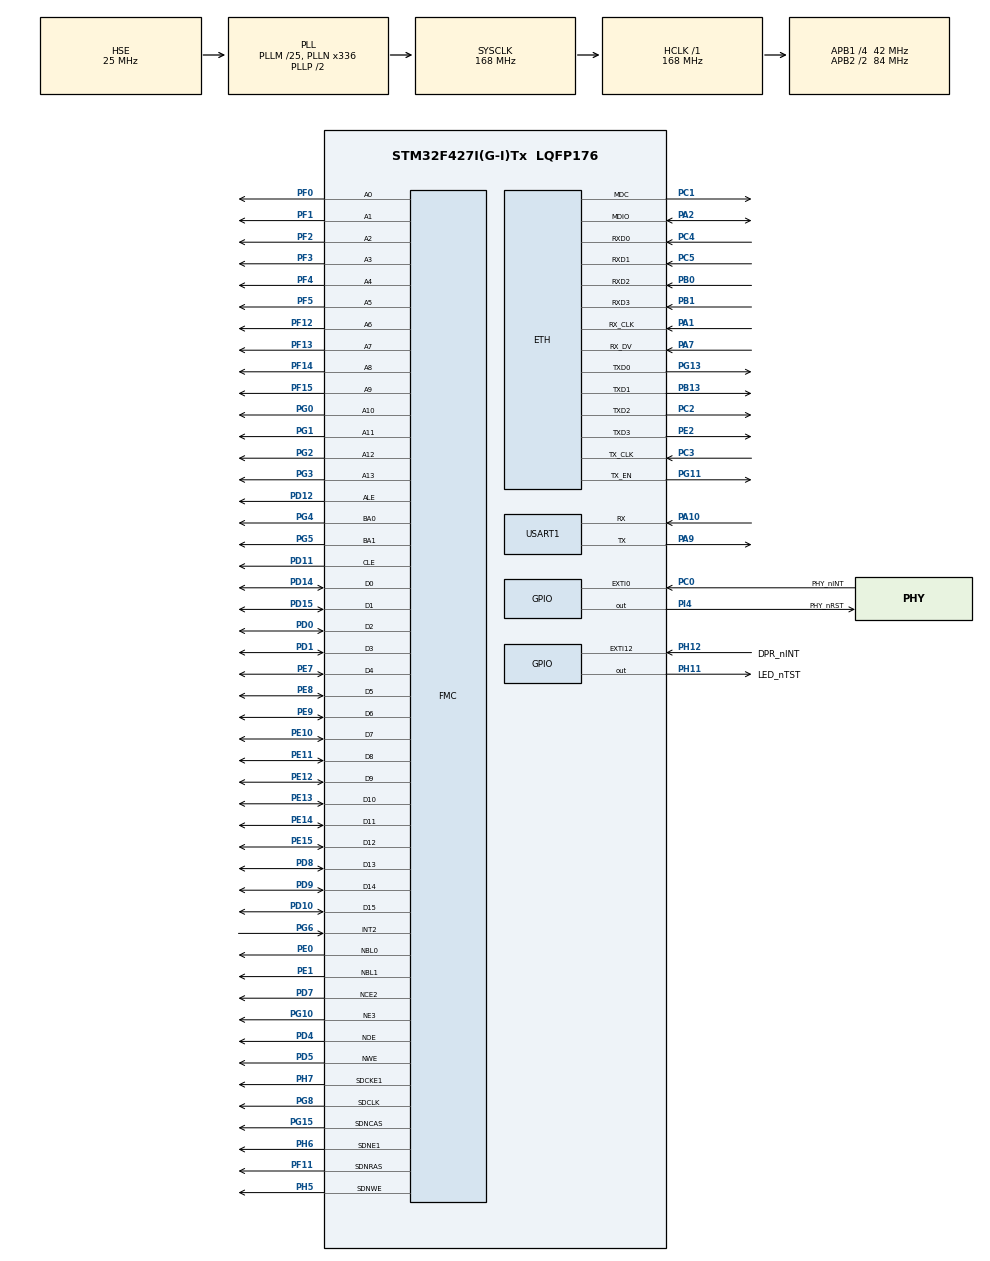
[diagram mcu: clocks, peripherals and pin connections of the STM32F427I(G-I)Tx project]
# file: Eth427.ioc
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ETH.MediaInterface=ETH_MEDIA_INTERFACE_MII
ETH.PHY_Name_MII=userPHY
ETH.PHY_User_Name=KSZ8873
ETH.PhyAddress=1
FMC.AddressSetupTime3=2
FMC.BusTurnAroundDuration3=5
FMC.CASLatency2=FMC_SDRAM_CAS_LATENCY_3
FMC.ColumnBitsNumber2=FMC_SDRAM_COLUMN_BITS_NUM_9
FMC.DataSetupTime3=6
FMC.ExitSelfRefreshDelay2=7
FMC.ExtendedAddressSetupTime3=2
FMC.ExtendedBusTurnAroundDuration3=5
FMC.ExtendedDataSetupTime3=6
FMC.ExtendedMode3=FMC_EXTENDED_MODE_ENABLE
FMC.LoadToActiveDelay2=2
FMC.RCDDelay2=2
FMC.RPDelay2=2
FMC.ReadBurst2=FMC_SDRAM_RBURST_DISABLE
FMC.ReadPipeDelay2=FMC_SDRAM_RPIPE_DELAY_1
FMC.RowCycleDelay2=7
FMC.SDClockPeriod2=FMC_SDRAM_CLOCK_PERIOD_2
FMC.SelfRefreshTime2=4
FMC.WriteOperation3=FMC_WRITE_OPERATION_ENABLE
FMC.WriteRecoveryTime2=3
FREERTOS.Tasks01=defaultTask,0,128,StartDefaultTask,Default,NULL
FREERTOS.configTOTAL_HEAP_SIZE=65536
LWIP.CHECKSUM_BY_HARDWARE=1
LWIP.GATEWAY_ADDRESS=192.168.001.001
LWIP.ICMP_TTL=63
LWIP.IP_ADDRESS=192.168.001.155
LWIP.LWIP_DHCP=0
LWIP.LWIP_NETIF_LINK_CALLBACK=0
LWIP.LWIP_SNTP=1
LWIP.LWIP_STATS=1
LWIP.MEMP_MEM_MALLOC=0
LWIP.MEMP_NUM_NETCONN=8
LWIP.MEMP_NUM_TCP_PCB=8
LWIP.MEMP_NUM_TCP_PCB_LISTEN=3
LWIP.MEMP_NUM_UDP_PCB=4
LWIP.MEM_SIZE=1600
LWIP.NETMASK_ADDRESS=255.255.255.000
LWIP.TCP_TTL=64
LWIP.Version=v2.0.3_Cube
Mcu.Family=STM32F4
Mcu.Name=STM32F427I(G-I)Tx
Mcu.Package=LQFP176
NVIC.ETH_IRQn=true\:5\:0\:false\:false\:true\:true\:true
NVIC.PriorityGroup=NVIC_PRIORITYGROUP_4
NVIC.TIM8_UP_TIM13_IRQn=true\:0\:0\:false\:false\:true\:false\:false
NVIC.TimeBase=TIM8_UP_TIM13_IRQn
NVIC.TimeBaseIP=TIM13
PA1.Mode=MII Full Duplex Only
PA1.Signal=ETH_RX_CLK
PA10.Mode=Asynchronous
PA10.Signal=USART1_RX
PA13.Mode=JTAG_5_pins
PA13.Signal=SYS_JTMS-SWDIO
PA14.Mode=JTAG_5_pins
PA14.Signal=SYS_JTCK-SWCLK
PA15.Mode=JTAG_5_pins
PA15.Signal=SYS_JTDI
PA2.Mode=MII Full Duplex Only
PA2.Signal=ETH_MDIO
PA3.Signal=ETH_COL
PA7.Mode=MII Full Duplex Only
PA7.Signal=ETH_RX_DV
PA9.Mode=Asynchronous
PA9.Signal=USART1_TX
PB0.Mode=MII Full Duplex Only
PB0.Signal=ETH_RXD2
PB1.Mode=MII Full Duplex Only
PB1.Signal=ETH_RXD3
PB13.Mode=MII Full Duplex Only
PB13.Signal=ETH_TXD1
PB3.Mode=JTAG_5_pins
PB3.Signal=SYS_JTDO-SWO
PB4.Mode=JTAG_5_pins
PB4.Signal=SYS_JTRST
PC0.GPIO_Label=PHY_nINT
PC0.GPIO_ModeDefaultEXTI=GPIO_MODE_IT_FALLING
PC0.GPIO_PuPd=GPIO_PULLUP
PC0.Signal=GPXTI0
PC1.Mode=MII Full Duplex Only
PC1.Signal=ETH_MDC
PC14/OSC32_IN.Mode=LSE-External-Oscillator
PC14/OSC32_IN.Signal=RCC_OSC32_IN
PC15/OSC32_OUT.Mode=LSE-External-Oscillator
PC15/OSC32_OUT.Signal=RCC_OSC32_OUT
PC2.Mode=MII Full Duplex Only
PC2.Signal=ETH_TXD2
PC3.Mode=MII Full Duplex Only
PC3.Signal=ETH_TX_CLK
PC4.Mode=MII Full Duplex Only
PC4.Signal=ETH_RXD0
PC5.Mode=MII Full Duplex Only
PC5.Signal=ETH_RXD1
PD0.Signal=FMC_D2_DA2
PD1.Signal=FMC_D3_DA3
PD10.Signal=FMC_D15_DA15
PD11.Signal=FMC_A16_CLE
PD12.Signal=FMC_A17_ALE
PD14.Signal=FMC_D0_DA0
PD15.Signal=FMC_D1_DA1
PD4.Signal=FMC_NOE
PD5.Signal=FMC_NWE
PD7.Mode=NandChipSelect2_1
PD7.Signal=FMC_NCE2
PD8.Signal=FMC_D13_DA13
PD9.Signal=FMC_D14_DA14
PE0.Signal=FMC_NBL0
PE1.Signal=FMC_NBL1
PE10.Signal=FMC_D7_DA7
PE11.Signal=FMC_D8_DA8
PE12.Signal=FMC_D9_DA9
PE13.Signal=FMC_D10_DA10
PE14.Signal=FMC_D11_DA11
PE15.Signal=FMC_D12_DA12
PE2.Mode=MII Full Duplex Only
PE2.Signal=ETH_TXD3
PE7.Signal=FMC_D4_DA4
PE8.Signal=FMC_D5_DA5
PE9.Signal=FMC_D6_DA6
PF0.Signal=FMC_A0
PF1.Signal=FMC_A1
PF11.Signal=FMC_SDNRAS
PF12.Signal=FMC_A6
PF13.Signal=FMC_A7
PF14.Signal=FMC_A8
PF15.Signal=FMC_A9
PF2.Signal=FMC_A2
PF3.Signal=FMC_A3
PF4.Signal=FMC_A4
PF5.Signal=FMC_A5
PG0.Signal=FMC_A10
PG1.Signal=FMC_A11
PG10.Mode=NorPsramChipSelect3_3
PG10.Signal=FMC_NE3
PG11.Mode=MII Full Duplex Only
PG11.Signal=ETH_TX_EN
PG13.Mode=MII Full Duplex Only
PG13.Signal=ETH_TXD0
PG15.Signal=FMC_SDNCAS
PG2.Signal=FMC_A12
PG3.Signal=FMC_A13
PG4.Signal=FMC_A14_BA0
PG5.Signal=FMC_A15_BA1
PG6.Signal=FMC_INT2
PG8.Signal=FMC_SDCLK
PH0/OSC_IN.Mode=HSE-External-Oscillator
PH0/OSC_IN.Signal=RCC_OSC_IN
PH1/OSC_OUT.Mode=HSE-External-Oscillator
PH1/OSC_OUT.Signal=RCC_OSC_OUT
PH11.GPIO_Label=LED_nTST
PH11.Signal=GPIO_Output
PH12.GPIO_Label=DPR_nINT
PH12.Signal=GPXTI12
PH5.Signal=FMC_SDNWE
PH6.Mode=SdramChipSelect2_2
PH6.Signal=FMC_SDNE1
PH7.Mode=SdramChipSelect2_2
PH7.Signal=FMC_SDCKE1
PI4.GPIO_Label=PHY_nRST
PI4.Signal=GPIO_Output
ProjectManager.HeapSize=0x10000
ProjectManager.StackSize=0x2000
ProjectManager.TargetToolchain=EWARM V7
RCC.48MHZClocksFreq_Value=84000000
RCC.AHBFreq_Value=168000000
RCC.APB1CLKDivider=RCC_HCLK_DIV4
RCC.APB1Freq_Value=42000000
RCC.APB1TimFreq_Value=84000000
RCC.APB2CLKDivider=RCC_HCLK_DIV2
RCC.APB2Freq_Value=84000000
RCC.APB2TimFreq_Value=168000000
RCC.CortexFreq_Value=168000000
RCC.HCLKFreq_Value=168000000
RCC.HSE_VALUE=25000000
RCC.HSI_VALUE=16000000
RCC.PLLM=25
RCC.PLLN=336
RCC.PLLSourceVirtual=RCC_PLLSOURCE_HSE
RCC.SYSCLKFreq_VALUE=168000000
RCC.SYSCLKSource=RCC_SYSCLKSOURCE_PLLCLK
RCC.VCOOutputFreq_Value=336000000
SH.FMC_A0.0=FMC_A0,14b-a3
SH.FMC_A0.1=FMC_A0,13b-sda2
SH.FMC_A1.0=FMC_A1,14b-a3
SH.FMC_A1.1=FMC_A1,13b-sda2
SH.FMC_A10.0=FMC_A10,14b-a3
SH.FMC_A10.1=FMC_A10,13b-sda2
SH.FMC_A11.0=FMC_A11,14b-a3
SH.FMC_A11.1=FMC_A11,13b-sda2
SH.FMC_A12.0=FMC_A12,14b-a3
SH.FMC_A12.1=FMC_A12,13b-sda2
SH.FMC_A13.0=FMC_A13,14b-a3
SH.FMC_A14_BA0.0=FMC_BA0,FourSdramBanks2
SH.FMC_A15_BA1.0=FMC_BA1,FourSdramBanks2
SH.FMC_A16_CLE.0=FMC_CLE,8b-dmux1
SH.FMC_A17_ALE.0=FMC_ALE,8b-dmux1
SH.FMC_A2.0=FMC_A2,14b-a3
SH.FMC_A2.1=FMC_A2,13b-sda2
SH.FMC_A3.0=FMC_A3,14b-a3
SH.FMC_A3.1=FMC_A3,13b-sda2
SH.FMC_A4.0=FMC_A4,14b-a3
SH.FMC_A4.1=FMC_A4,13b-sda2
SH.FMC_A5.0=FMC_A5,14b-a3
SH.FMC_A5.1=FMC_A5,13b-sda2
SH.FMC_A6.0=FMC_A6,14b-a3
SH.FMC_A6.1=FMC_A6,13b-sda2
SH.FMC_A7.0=FMC_A7,14b-a3
SH.FMC_A7.1=FMC_A7,13b-sda2
SH.FMC_A8.0=FMC_A8,14b-a3
SH.FMC_A8.1=FMC_A8,13b-sda2
SH.FMC_A9.0=FMC_A9,14b-a3
SH.FMC_A9.1=FMC_A9,13b-sda2
SH.FMC_D0_DA0.0=FMC_D0,16b-d3
SH.FMC_D0_DA0.1=FMC_D0,8b-dmux1
SH.FMC_D0_DA0.2=FMC_D0,sd-16b-d2
SH.FMC_D10_DA10.0=FMC_D10,16b-d3
SH.FMC_D10_DA10.1=FMC_D10,sd-16b-d2
SH.FMC_D11_DA11.0=FMC_D11,16b-d3
SH.FMC_D11_DA11.1=FMC_D11,sd-16b-d2
SH.FMC_D12_DA12.0=FMC_D12,16b-d3
SH.FMC_D12_DA12.1=FMC_D12,sd-16b-d2
SH.FMC_D13_DA13.0=FMC_D13,16b-d3
SH.FMC_D13_DA13.1=FMC_D13,sd-16b-d2
SH.FMC_D14_DA14.0=FMC_D14,16b-d3
SH.FMC_D14_DA14.1=FMC_D14,sd-16b-d2
SH.FMC_D15_DA15.0=FMC_D15,16b-d3
SH.FMC_D15_DA15.1=FMC_D15,sd-16b-d2
SH.FMC_D1_DA1.0=FMC_D1,16b-d3
SH.FMC_D1_DA1.1=FMC_D1,8b-dmux1
SH.FMC_D1_DA1.2=FMC_D1,sd-16b-d2
SH.FMC_D2_DA2.0=FMC_D2,16b-d3
SH.FMC_D2_DA2.1=FMC_D2,8b-dmux1
SH.FMC_D2_DA2.2=FMC_D2,sd-16b-d2
SH.FMC_D3_DA3.0=FMC_D3,16b-d3
SH.FMC_D3_DA3.1=FMC_D3,8b-dmux1
SH.FMC_D3_DA3.2=FMC_D3,sd-16b-d2
SH.FMC_D4_DA4.0=FMC_D4,16b-d3
SH.FMC_D4_DA4.1=FMC_D4,8b-dmux1
SH.FMC_D4_DA4.2=FMC_D4,sd-16b-d2
SH.FMC_D5_DA5.0=FMC_D5,16b-d3
SH.FMC_D5_DA5.1=FMC_D5,8b-dmux1
SH.FMC_D5_DA5.2=FMC_D5,sd-16b-d2
SH.FMC_D6_DA6.0=FMC_D6,16b-d3
SH.FMC_D6_DA6.1=FMC_D6,8b-dmux1
SH.FMC_D6_DA6.2=FMC_D6,sd-16b-d2
SH.FMC_D7_DA7.0=FMC_D7,16b-d3
SH.FMC_D7_DA7.1=FMC_D7,8b-dmux1
SH.FMC_D7_DA7.2=FMC_D7,sd-16b-d2
SH.FMC_D8_DA8.0=FMC_D8,16b-d3
SH.FMC_D8_DA8.1=FMC_D8,sd-16b-d2
SH.FMC_D9_DA9.0=FMC_D9,16b-d3
SH.FMC_D9_DA9.1=FMC_D9,sd-16b-d2
SH.FMC_INT2.0=FMC_INT2,Interrupt21
SH.FMC_NBL0.0=FMC_NBL0,2ByteEnable3
SH.FMC_NBL0.1=FMC_NBL0,Sd2ByteEnable2
SH.FMC_NBL1.0=FMC_NBL1,2ByteEnable3
SH.FMC_NBL1.1=FMC_NBL1,Sd2ByteEnable2
SH.FMC_NOE.0=FMC_NOE,Sram3
SH.FMC_NOE.1=FMC_NOE,8b-dmux1
SH.FMC_NWE.0=FMC_NWE,Sram3
SH.FMC_NWE.1=FMC_NWE,8b-dmux1
SH.FMC_SDCLK.0=FMC_SDCLK,13b-sda2
SH.FMC_SDNCAS.0=FMC_SDNCAS,13b-sda2
SH.FMC_SDNRAS.0=FMC_SDNRAS,13b-sda2
SH.FMC_SDNWE.0=FMC_SDNWE,13b-sda2
USART1.VirtualMode=VM_ASYNC
VP_FREERTOS_VS_ENABLE.Mode=Enabled
VP_LWIP_VS_Enabled.Mode=Enabled
VP_SYS_VS_tim13.Mode=TIM13
board=custom

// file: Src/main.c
/* USER CODE BEGIN Header */
/**
  ******************************************************************************
  * @file           : main.c
  * @brief          : Main program body
  ******************************************************************************
  ** This notice applies to any and all portions of this file
  * that are not between comment pairs USER CODE BEGIN and
  * USER CODE END. Other portions of this file, whether
  * inserted by the user or by software development tools
  * are owned by their respective copyright owners.
  *
  * COPYRIGHT(c) 2019 STMicroelectronics
  *
  * Redistribution and use in source and binary forms, with or without modification,
  * are permitted provided that the following conditions are met:
  *   1. Redistributions of source code must retain the above copyright notice,
  *      this list of conditions and the following disclaimer.
  *   2. Redistributions in binary form must reproduce the above copyright notice,
  *      this list of conditions and the following disclaimer in the documentation
  *      and/or other materials provided with the distribution.
  *   3. Neither the name of STMicroelectronics nor the names of its contributors
  *      may be used to endorse or promote products derived from this software
  *      without specific prior written permission.
  *
  * THIS SOFTWARE IS PROVIDED BY THE COPYRIGHT HOLDERS AND CONTRIBUTORS "AS IS"
  * AND ANY EXPRESS OR IMPLIED WARRANTIES, INCLUDING, BUT NOT LIMITED TO, THE
  * IMPLIED WARRANTIES OF MERCHANTABILITY AND FITNESS FOR A PARTICULAR PURPOSE ARE
  * DISCLAIMED. IN NO EVENT SHALL THE COPYRIGHT HOLDER OR CONTRIBUTORS BE LIABLE
  * FOR ANY DIRECT, INDIRECT, INCIDENTAL, SPECIAL, EXEMPLARY, OR CONSEQUENTIAL
  * DAMAGES (INCLUDING, BUT NOT LIMITED TO, PROCUREMENT OF SUBSTITUTE GOODS OR
  * SERVICES; LOSS OF USE, DATA, OR PROFITS; OR BUSINESS INTERRUPTION) HOWEVER
  * CAUSED AND ON ANY THEORY OF LIABILITY, WHETHER IN CONTRACT, STRICT LIABILITY,
  * OR TORT (INCLUDING NEGLIGENCE OR OTHERWISE) ARISING IN ANY WAY OUT OF THE USE
  * OF THIS SOFTWARE, EVEN IF ADVISED OF THE POSSIBILITY OF SUCH DAMAGE.
  *
  ******************************************************************************
  */
/* USER CODE END Header */

#include "main.h"
#include "cmsis_os.h"
#include "lwip.h"

/* USER CODE BEGIN Includes */
// by Sooan Choi
#include "MdTcpSrv.h"		// Modbus Tcp
#include "dpram.h"

/* USER CODE END Includes */

UART_HandleTypeDef huart1;

SRAM_HandleTypeDef hsram3;
NAND_HandleTypeDef hnand1;
SDRAM_HandleTypeDef hsdram2;

osThreadId defaultTaskHandle;

void SystemClock_Config(void);
static void MX_GPIO_Init(void);
static void MX_USART1_UART_Init(void);
static void MX_FMC_Init(void);
void StartDefaultTask(void const * argument);

/* USER CODE BEGIN PFP */
static void BSP_SDRAM_Initialization_Sequence(SDRAM_HandleTypeDef *hsdram, FMC_SDRAM_CommandTypeDef *Command);
/* USER CODE END PFP */

/* USER CODE BEGIN 0 */
#ifdef __GNUC__
int  _write(int file, char *ptr, int len)
{
	HAL_UART_Transmit(&huart1, (uint8_t*)ptr, len, 10 );

	return len;
}
#else
int fputc(int ch, FILE *f)
{
  HAL_UART_Transmit(&huart1, (uint8_t *)&ch, 1, 0xFFFF);

  return ch;
}
#endif /* __GNUC__ */
/* USER CODE END 0 */

int main(void)
{

  /* MCU Configuration--------------------------------------------------------*/

  /* Reset of all peripherals, Initializes the Flash interface and the Systick. */
  HAL_Init();

  /* Configure the system clock */
  SystemClock_Config();

  /* Initialize all configured peripherals */
  MX_GPIO_Init();
  MX_USART1_UART_Init();
  MX_FMC_Init();
  /* USER CODE BEGIN 2 */

	FMC_SDRAM_CommandTypeDef Command;
	BSP_SDRAM_Initialization_Sequence(&hsdram2, &Command);

	printf("Promet-S Ethernet for STM32F4xx. Ver 1.0b0\r\n");
	printf("Compiled on %s, %s\r\n", __TIME__, __DATE__);
	printf("Copywrite by Sooan. Neopis Co., Ltd. South Korea\r\n\n");

	printf("Running on System Clock Speed %3uMHz\r\n", (unsigned)HAL_RCC_GetSysClockFreq()/1000000);
	printf("HCLK   = %3uMHz\r\n", (unsigned)HAL_RCC_GetHCLKFreq()/1000000);
	printf("PCLK1  = %3uMHz\r\n", (unsigned)HAL_RCC_GetPCLK1Freq()/1000000);
	printf("PCLK2  = %3uMHz\r\n", (unsigned)HAL_RCC_GetPCLK2Freq()/1000000);
	printf("\n");

	dpram_init();

  /* USER CODE END 2 */

  /* Create the thread(s) */
  /* definition and creation of defaultTask */
  osThreadDef(defaultTask, StartDefaultTask, osPriorityNormal, 0, 128);
  defaultTaskHandle = osThreadCreate(osThread(defaultTask), NULL);

  /* Start scheduler */
  osKernelStart();

  /* We should never get here as control is now taken by the scheduler */

  /* Infinite loop */
  while (1)
  {

  }
}

void SystemClock_Config(void)
{
  RCC_OscInitTypeDef RCC_OscInitStruct = {0};
  RCC_ClkInitTypeDef RCC_ClkInitStruct = {0};

  /**Configure the main internal regulator output voltage
  */
  __HAL_RCC_PWR_CLK_ENABLE();
  __HAL_PWR_VOLTAGESCALING_CONFIG(PWR_REGULATOR_VOLTAGE_SCALE1);
  /**Initializes the CPU, AHB and APB busses clocks
  */
  RCC_OscInitStruct.OscillatorType = RCC_OSCILLATORTYPE_HSE;
  RCC_OscInitStruct.HSEState = RCC_HSE_ON;
  RCC_OscInitStruct.PLL.PLLState = RCC_PLL_ON;
  RCC_OscInitStruct.PLL.PLLSource = RCC_PLLSOURCE_HSE;
  RCC_OscInitStruct.PLL.PLLM = 25;
  RCC_OscInitStruct.PLL.PLLN = 336;
  RCC_OscInitStruct.PLL.PLLP = RCC_PLLP_DIV2;
  RCC_OscInitStruct.PLL.PLLQ = 4;
  if (HAL_RCC_OscConfig(&RCC_OscInitStruct) != HAL_OK)
  {
    Error_Handler();
  }
  /**Initializes the CPU, AHB and APB busses clocks
  */
  RCC_ClkInitStruct.ClockType = RCC_CLOCKTYPE_HCLK|RCC_CLOCKTYPE_SYSCLK
                              |RCC_CLOCKTYPE_PCLK1|RCC_CLOCKTYPE_PCLK2;
  RCC_ClkInitStruct.SYSCLKSource = RCC_SYSCLKSOURCE_PLLCLK;
  RCC_ClkInitStruct.AHBCLKDivider = RCC_SYSCLK_DIV1;
  RCC_ClkInitStruct.APB1CLKDivider = RCC_HCLK_DIV4;
  RCC_ClkInitStruct.APB2CLKDivider = RCC_HCLK_DIV2;

  if (HAL_RCC_ClockConfig(&RCC_ClkInitStruct, FLASH_LATENCY_5) != HAL_OK)
  {
    Error_Handler();
  }
}

static void MX_USART1_UART_Init(void)
{

  huart1.Instance = USART1;
  huart1.Init.BaudRate = 115200;
  huart1.Init.WordLength = UART_WORDLENGTH_8B;
  huart1.Init.StopBits = UART_STOPBITS_1;
  huart1.Init.Parity = UART_PARITY_NONE;
  huart1.Init.Mode = UART_MODE_TX_RX;
  huart1.Init.HwFlowCtl = UART_HWCONTROL_NONE;
  huart1.Init.OverSampling = UART_OVERSAMPLING_16;
  if (HAL_UART_Init(&huart1) != HAL_OK)
  {
    Error_Handler();
  }

}

/* FMC initialization function */
static void MX_FMC_Init(void)
{
  FMC_NORSRAM_TimingTypeDef Timing;
  FMC_NORSRAM_TimingTypeDef ExtTiming;
  FMC_NAND_PCC_TimingTypeDef ComSpaceTiming;
  FMC_NAND_PCC_TimingTypeDef AttSpaceTiming;
  FMC_SDRAM_TimingTypeDef SdramTiming;

  /** Perform the SRAM3 memory initialization sequence
  */
  hsram3.Instance = FMC_NORSRAM_DEVICE;
  hsram3.Extended = FMC_NORSRAM_EXTENDED_DEVICE;
  /* hsram3.Init */
  hsram3.Init.NSBank = FMC_NORSRAM_BANK3;
  hsram3.Init.DataAddressMux = FMC_DATA_ADDRESS_MUX_DISABLE;
  hsram3.Init.MemoryType = FMC_MEMORY_TYPE_SRAM;
  hsram3.Init.MemoryDataWidth = FMC_NORSRAM_MEM_BUS_WIDTH_16;
  hsram3.Init.BurstAccessMode = FMC_BURST_ACCESS_MODE_DISABLE;
  hsram3.Init.WaitSignalPolarity = FMC_WAIT_SIGNAL_POLARITY_LOW;
  hsram3.Init.WrapMode = FMC_WRAP_MODE_DISABLE;
  hsram3.Init.WaitSignalActive = FMC_WAIT_TIMING_BEFORE_WS;
  hsram3.Init.WriteOperation = FMC_WRITE_OPERATION_ENABLE;
  hsram3.Init.WaitSignal = FMC_WAIT_SIGNAL_DISABLE;
  hsram3.Init.ExtendedMode = FMC_EXTENDED_MODE_ENABLE;
  hsram3.Init.AsynchronousWait = FMC_ASYNCHRONOUS_WAIT_DISABLE;
  hsram3.Init.WriteBurst = FMC_WRITE_BURST_DISABLE;
  hsram3.Init.ContinuousClock = FMC_CONTINUOUS_CLOCK_SYNC_ONLY;
  hsram3.Init.PageSize = FMC_PAGE_SIZE_NONE;
  /* Timing */
  Timing.AddressSetupTime = 2;
  Timing.AddressHoldTime = 15;
  Timing.DataSetupTime = 6;
  Timing.BusTurnAroundDuration = 5;
  Timing.CLKDivision = 16;
  Timing.DataLatency = 17;
  Timing.AccessMode = FMC_ACCESS_MODE_A;
  /* ExtTiming */
  ExtTiming.AddressSetupTime = 2;
  ExtTiming.AddressHoldTime = 15;
  ExtTiming.DataSetupTime = 6;
  ExtTiming.BusTurnAroundDuration = 5;
  ExtTiming.CLKDivision = 16;
  ExtTiming.DataLatency = 17;
  ExtTiming.AccessMode = FMC_ACCESS_MODE_A;

  if (HAL_SRAM_Init(&hsram3, &Timing, &ExtTiming) != HAL_OK)
  {
    Error_Handler( );
  }

  /** Perform the NAND1 memory initialization sequence
  */
  hnand1.Instance = FMC_NAND_DEVICE;
  /* hnand1.Init */
  hnand1.Init.NandBank = FMC_NAND_BANK2;
  hnand1.Init.Waitfeature = FMC_NAND_PCC_WAIT_FEATURE_ENABLE;
  hnand1.Init.MemoryDataWidth = FMC_NAND_PCC_MEM_BUS_WIDTH_8;
  hnand1.Init.EccComputation = FMC_NAND_ECC_DISABLE;
  hnand1.Init.ECCPageSize = FMC_NAND_ECC_PAGE_SIZE_256BYTE;
  hnand1.Init.TCLRSetupTime = 0;
  hnand1.Init.TARSetupTime = 0;
  /* hnand1.Config */
  hnand1.Config.PageSize = 0;
  hnand1.Config.SpareAreaSize = 0;
  hnand1.Config.BlockSize = 0;
  hnand1.Config.BlockNbr = 0;
  hnand1.Config.PlaneNbr = 0;
  hnand1.Config.PlaneSize = 0;
  hnand1.Config.ExtraCommandEnable = DISABLE;
  /* ComSpaceTiming */
  ComSpaceTiming.SetupTime = 252;
  ComSpaceTiming.WaitSetupTime = 252;
  ComSpaceTiming.HoldSetupTime = 252;
  ComSpaceTiming.HiZSetupTime = 252;
  /* AttSpaceTiming */
  AttSpaceTiming.SetupTime = 252;
  AttSpaceTiming.WaitSetupTime = 252;
  AttSpaceTiming.HoldSetupTime = 252;
  AttSpaceTiming.HiZSetupTime = 252;

  if (HAL_NAND_Init(&hnand1, &ComSpaceTiming, &AttSpaceTiming) != HAL_OK)
  {
    Error_Handler( );
  }

  /** Perform the SDRAM2 memory initialization sequence
  */
  hsdram2.Instance = FMC_SDRAM_DEVICE;
  /* hsdram2.Init */
  hsdram2.Init.SDBank = FMC_SDRAM_BANK2;
  hsdram2.Init.ColumnBitsNumber = FMC_SDRAM_COLUMN_BITS_NUM_9;
  hsdram2.Init.RowBitsNumber = FMC_SDRAM_ROW_BITS_NUM_13;
  hsdram2.Init.MemoryDataWidth = FMC_SDRAM_MEM_BUS_WIDTH_16;
  hsdram2.Init.InternalBankNumber = FMC_SDRAM_INTERN_BANKS_NUM_4;
  hsdram2.Init.CASLatency = FMC_SDRAM_CAS_LATENCY_3;
  hsdram2.Init.WriteProtection = FMC_SDRAM_WRITE_PROTECTION_DISABLE;
  hsdram2.Init.SDClockPeriod = FMC_SDRAM_CLOCK_PERIOD_2;
  hsdram2.Init.ReadBurst = FMC_SDRAM_RBURST_DISABLE;
  hsdram2.Init.ReadPipeDelay = FMC_SDRAM_RPIPE_DELAY_1;
  /* SdramTiming */
  SdramTiming.LoadToActiveDelay = 2;
  SdramTiming.ExitSelfRefreshDelay = 7;
  SdramTiming.SelfRefreshTime = 4;
  SdramTiming.RowCycleDelay = 7;
  SdramTiming.WriteRecoveryTime = 3;
  SdramTiming.RPDelay = 2;
  SdramTiming.RCDDelay = 2;

  if (HAL_SDRAM_Init(&hsdram2, &SdramTiming) != HAL_OK)
  {
    Error_Handler( );
  }

}

static void MX_GPIO_Init(void)
{
  GPIO_InitTypeDef GPIO_InitStruct = {0};

  /* GPIO Ports Clock Enable */
  __HAL_RCC_GPIOE_CLK_ENABLE();
  __HAL_RCC_GPIOC_CLK_ENABLE();
  __HAL_RCC_GPIOF_CLK_ENABLE();
  __HAL_RCC_GPIOH_CLK_ENABLE();
  __HAL_RCC_GPIOA_CLK_ENABLE();
  __HAL_RCC_GPIOB_CLK_ENABLE();
  __HAL_RCC_GPIOG_CLK_ENABLE();
  __HAL_RCC_GPIOD_CLK_ENABLE();
  __HAL_RCC_GPIOI_CLK_ENABLE();

  /*Configure GPIO pin Output Level */
  HAL_GPIO_WritePin(LED_nTST_GPIO_Port, LED_nTST_Pin, GPIO_PIN_RESET);

  /*Configure GPIO pin Output Level */
  HAL_GPIO_WritePin(PHY_nRST_GPIO_Port, PHY_nRST_Pin, GPIO_PIN_RESET);

  /*Configure GPIO pin : PHY_nINT_Pin */
  GPIO_InitStruct.Pin = PHY_nINT_Pin;
  GPIO_InitStruct.Mode = GPIO_MODE_IT_FALLING;
  GPIO_InitStruct.Pull = GPIO_PULLUP;
  HAL_GPIO_Init(PHY_nINT_GPIO_Port, &GPIO_InitStruct);

  /*Configure GPIO pin : LED_nTST_Pin */
  GPIO_InitStruct.Pin = LED_nTST_Pin;
  GPIO_InitStruct.Mode = GPIO_MODE_OUTPUT_PP;
  GPIO_InitStruct.Pull = GPIO_NOPULL;
  GPIO_InitStruct.Speed = GPIO_SPEED_FREQ_LOW;
  HAL_GPIO_Init(LED_nTST_GPIO_Port, &GPIO_InitStruct);

  /*Configure GPIO pin : DPR_nINT_Pin */
  GPIO_InitStruct.Pin = DPR_nINT_Pin;
  GPIO_InitStruct.Mode = GPIO_MODE_IT_RISING;
  GPIO_InitStruct.Pull = GPIO_NOPULL;
  HAL_GPIO_Init(DPR_nINT_GPIO_Port, &GPIO_InitStruct);

  /*Configure GPIO pin : PHY_nRST_Pin */
  GPIO_InitStruct.Pin = PHY_nRST_Pin;
  GPIO_InitStruct.Mode = GPIO_MODE_OUTPUT_PP;
  GPIO_InitStruct.Pull = GPIO_NOPULL;
  GPIO_InitStruct.Speed = GPIO_SPEED_FREQ_LOW;
  HAL_GPIO_Init(PHY_nRST_GPIO_Port, &GPIO_InitStruct);

}

/* USER CODE BEGIN 4 */
#define SDRAM_TIMEOUT							((uint32_t)0x1000)
#define REFRESH_COUNT							((uint32_t)0x1386)
#define SDRAM_MODEREG_BURST_LENGTH_1             ((uint16_t)0x0000)
#define SDRAM_MODEREG_BURST_LENGTH_2             ((uint16_t)0x0001)
#define SDRAM_MODEREG_BURST_LENGTH_4             ((uint16_t)0x0002)
#define SDRAM_MODEREG_BURST_LENGTH_8             ((uint16_t)0x0004)
#define SDRAM_MODEREG_BURST_TYPE_SEQUENTIAL      ((uint16_t)0x0000)
#define SDRAM_MODEREG_BURST_TYPE_INTERLEAVED     ((uint16_t)0x0008)
#define SDRAM_MODEREG_CAS_LATENCY_2              ((uint16_t)0x0020)
#define SDRAM_MODEREG_CAS_LATENCY_3              ((uint16_t)0x0030)
#define SDRAM_MODEREG_OPERATING_MODE_STANDARD    ((uint16_t)0x0000)
#define SDRAM_MODEREG_WRITEBURST_MODE_PROGRAMMED ((uint16_t)0x0000)
#define SDRAM_MODEREG_WRITEBURST_MODE_SINGLE     ((uint16_t)0x0200)

static void BSP_SDRAM_Initialization_Sequence(SDRAM_HandleTypeDef *hsdram, FMC_SDRAM_CommandTypeDef *Command)
{
  __IO uint32_t tmpmrd =0;
  /* Step 3:  Configure a clock configuration enable command */
  Command->CommandMode = FMC_SDRAM_CMD_CLK_ENABLE;
  Command->CommandTarget = FMC_SDRAM_CMD_TARGET_BANK2;
  Command->AutoRefreshNumber = 1;
  Command->ModeRegisterDefinition = 0;

  /* Send the command */
  HAL_SDRAM_SendCommand(hsdram, Command, SDRAM_TIMEOUT);

  /* Step 4: Insert 100 us minimum delay */
  /* Inserted delay is equal to 10 ms due to systick time base unit (ms) */
  HAL_Delay(10);

  /* Step 5: Configure a PALL (precharge all) command */
  Command->CommandMode = FMC_SDRAM_CMD_PALL;
  Command->CommandTarget = FMC_SDRAM_CMD_TARGET_BANK2;
  Command->AutoRefreshNumber = 1;
  Command->ModeRegisterDefinition = 0;

  /* Send the command */
  HAL_SDRAM_SendCommand(hsdram, Command, SDRAM_TIMEOUT);

  /* Step 6 : Configure a Auto-Refresh command */
  Command->CommandMode = FMC_SDRAM_CMD_AUTOREFRESH_MODE;
  Command->CommandTarget = FMC_SDRAM_CMD_TARGET_BANK2;
  Command->AutoRefreshNumber = 4;
  Command->ModeRegisterDefinition = 0;

  /* Send the command */
  HAL_SDRAM_SendCommand(hsdram, Command, SDRAM_TIMEOUT);

  /* Step 7: Program the external memory mode register */
  tmpmrd = (uint32_t)SDRAM_MODEREG_BURST_LENGTH_2          |
                     SDRAM_MODEREG_BURST_TYPE_SEQUENTIAL   |
                     SDRAM_MODEREG_CAS_LATENCY_3           |
                     SDRAM_MODEREG_OPERATING_MODE_STANDARD |
                     SDRAM_MODEREG_WRITEBURST_MODE_SINGLE;

  Command->CommandMode = FMC_SDRAM_CMD_LOAD_MODE;
  Command->CommandTarget = FMC_SDRAM_CMD_TARGET_BANK2;
  Command->AutoRefreshNumber = 1;
  Command->ModeRegisterDefinition = tmpmrd;

  /* Send the command */
  HAL_SDRAM_SendCommand(hsdram, Command, SDRAM_TIMEOUT);

  /* Step 8: Set the refresh rate counter */
  /* (15.62 us x Freq) - 20 */
  /* Set the device refresh counter */
  HAL_SDRAM_ProgramRefreshRate(hsdram, REFRESH_COUNT);
}
/* USER CODE END 4 */

void StartDefaultTask(void const * argument)
{
  /* init code for LWIP */
  MX_LWIP_Init();

  /* USER CODE BEGIN 5 */
  uint16_t port = 502;
  StartMdTcpServerTask(&port);

  /* Infinite loop */
  for(;;)
  {
    osDelay(1);
  }
  /* USER CODE END 5 */
}

void HAL_TIM_PeriodElapsedCallback(TIM_HandleTypeDef *htim)
{
  if (htim->Instance == TIM13) {
    HAL_IncTick();
  }
}

void Error_Handler(void)
{
}

/************************ (C) COPYRIGHT STMicroelectronics *****END OF FILE****/
